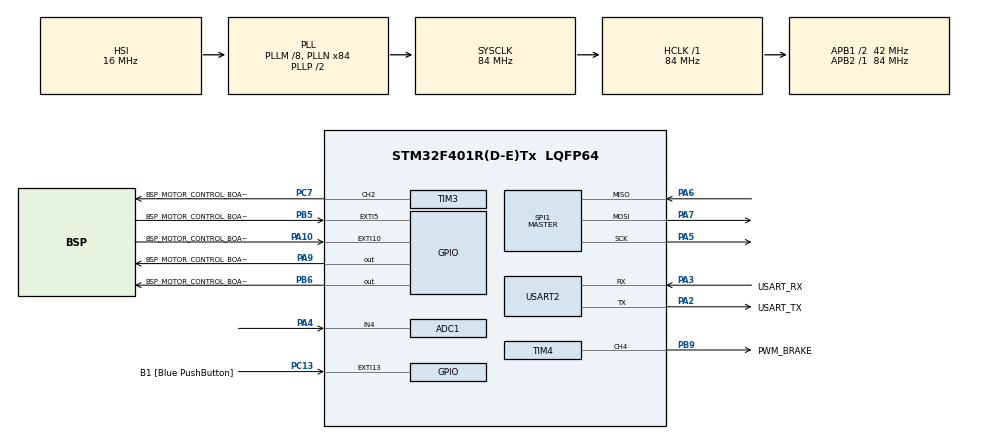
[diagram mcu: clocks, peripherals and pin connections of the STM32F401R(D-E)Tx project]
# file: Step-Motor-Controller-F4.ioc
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ADC1.Channel-4\#ChannelRegularConversion=ADC_CHANNEL_4
ADC1.NbrOfConversionFlag=1
ADC1.Rank-4\#ChannelRegularConversion=1
ADC1.SamplingTime-4\#ChannelRegularConversion=ADC_SAMPLETIME_3CYCLES
ADC1.master=1
Mcu.Family=STM32F4
Mcu.Name=STM32F401R(D-E)Tx
Mcu.Package=LQFP64
NVIC.EXTI15_10_IRQn=true\:0\:0\:false\:false\:true\:false\:true\:true
NVIC.EXTI9_5_IRQn=true\:0\:0\:false\:false\:true\:false\:true\:true
NVIC.PriorityGroup=NVIC_PRIORITYGROUP_4
NVIC.TIM2_IRQn=true\:15\:0\:true\:false\:true\:false\:false\:true
NVIC.TimeBase=TIM2_IRQn
NVIC.TimeBaseIP=TIM2
NVIC.USART2_IRQn=true\:0\:0\:true\:false\:true\:false\:true\:true
PA10.GPIO_Label=BSP_MOTOR_CONTROL_BOARD_FLAG
PA10.GPIO_ModeDefaultEXTI=GPIO_MODE_IT_FALLING
PA10.GPIO_PuPd=GPIO_PULLUP
PA10.Signal=GPXTI10
PA13.GPIO_Label=TMS
PA13.Mode=Serial_Wire
PA13.Signal=SYS_JTMS-SWDIO
PA14.GPIO_Label=TCK
PA14.Mode=Serial_Wire
PA14.Signal=SYS_JTCK-SWCLK
PA2.GPIO_Label=USART_TX
PA2.GPIO_Mode=GPIO_MODE_AF_PP
PA2.GPIO_PuPd=GPIO_NOPULL
PA2.GPIO_Speed=GPIO_SPEED_FREQ_LOW
PA2.Mode=Asynchronous
PA2.Signal=USART2_TX
PA3.GPIO_Label=USART_RX
PA3.GPIO_Mode=GPIO_MODE_AF_PP
PA3.GPIO_PuPd=GPIO_NOPULL
PA3.GPIO_Speed=GPIO_SPEED_FREQ_LOW
PA3.Mode=Asynchronous
PA3.Signal=USART2_RX
PA4.Signal=ADCx_IN4
PA5.GPIO_Speed=GPIO_SPEED_FREQ_LOW
PA5.Mode=Full_Duplex_Master
PA5.Signal=SPI1_SCK
PA6.GPIO_Speed=GPIO_SPEED_FREQ_LOW
PA6.Mode=Full_Duplex_Master
PA6.Signal=SPI1_MISO
PA7.GPIO_Speed=GPIO_SPEED_FREQ_LOW
PA7.Mode=Full_Duplex_Master
PA7.Signal=SPI1_MOSI
PA9.GPIO_Label=BSP_MOTOR_CONTROL_BOARD_STBY_RESET
PA9.Signal=GPIO_Output
PB5.GPIO_Label=BSP_MOTOR_CONTROL_BOARD_BUSY
PB5.GPIO_ModeDefaultEXTI=GPIO_MODE_IT_RISING_FALLING
PB5.GPIO_PuPd=GPIO_PULLUP
PB5.Signal=GPXTI5
PB6.GPIO_Label=BSP_MOTOR_CONTROL_BOARD_CS
PB6.GPIO_PuPd=GPIO_PULLUP
PB6.PinState=GPIO_PIN_SET
PB6.Signal=GPIO_Output
PB9.GPIO_Label=PWM_BRAKE
PB9.Signal=S_TIM4_CH4
PC13-ANTI_TAMP.GPIO_Label=B1 [Blue PushButton]
PC13-ANTI_TAMP.GPIO_ModeDefaultEXTI=GPIO_MODE_IT_FALLING
PC13-ANTI_TAMP.GPIO_PuPd=GPIO_NOPULL
PC13-ANTI_TAMP.Signal=GPXTI13
PC14-OSC32_IN.Mode=LSE-External-Oscillator
PC14-OSC32_IN.Signal=RCC_OSC32_IN
PC15-OSC32_OUT.Mode=LSE-External-Oscillator
PC15-OSC32_OUT.Signal=RCC_OSC32_OUT
PC7.GPIO_Label=BSP_MOTOR_CONTROL_BOARD_TIMER_STEP_CLOCK
PC7.Signal=S_TIM3_CH2
PH0\ -\ OSC_IN.Mode=HSE-External-Clock-Source
PH0\ -\ OSC_IN.Signal=RCC_OSC_IN
PH1\ -\ OSC_OUT.Mode=HSE-External-Clock-Source
PH1\ -\ OSC_OUT.Signal=RCC_OSC_OUT
ProjectManager.HeapSize=0x200
ProjectManager.StackSize=0x400
ProjectManager.TargetToolchain=STM32CubeIDE
RCC.48MHZClocksFreq_Value=24000000
RCC.AHBFreq_Value=84000000
RCC.APB1CLKDivider=RCC_HCLK_DIV2
RCC.APB1Freq_Value=42000000
RCC.APB1TimFreq_Value=84000000
RCC.APB2Freq_Value=84000000
RCC.APB2TimFreq_Value=84000000
RCC.CortexFreq_Value=84000000
RCC.HCLKFreq_Value=84000000
RCC.HSE_VALUE=8000000
RCC.HSI_VALUE=16000000
RCC.PLLM=8
RCC.PLLN=84
RCC.PLLQ=7
RCC.SYSCLKFreq_VALUE=84000000
RCC.SYSCLKSource=RCC_SYSCLKSOURCE_PLLCLK
RCC.VCOOutputFreq_Value=168000000
SH.ADCx_IN4.0=ADC1_IN4,IN4
SH.S_TIM3_CH2.0=TIM3_CH2,PWM Generation2 CH2
SH.S_TIM4_CH4.0=TIM4_CH4,PWM Generation4 CH4
SPI1.BaudRatePrescaler=SPI_BAUDRATEPRESCALER_32
SPI1.CLKPhase=SPI_PHASE_2EDGE
SPI1.CLKPolarity=SPI_POLARITY_HIGH
SPI1.Direction=SPI_DIRECTION_2LINES
SPI1.Mode=SPI_MODE_MASTER
SPI1.VirtualType=VM_MASTER
STMicroelectronics.X-CUBE-AZRTOS-F4.1.0.0.ThreadXCcRTOSJjThreadXJjCore=true
STMicroelectronics.X-CUBE-AZRTOS-F4.1.0.0.ThreadXCcRTOSJjThreadXJjLowOoPowerOosupport=true
STMicroelectronics.X-CUBE-AZRTOS-F4.1.0.0.ThreadXCcRTOSJjThreadXJjPerformanceInfo=true
STMicroelectronics.X-CUBE-AZRTOS-F4.1.0.0.ThreadXCcRTOSJjThreadXJjTraceXOosupport=true
STMicroelectronics.X-CUBE-AZRTOS-F4.1.0.0_IsAnAzureRtosMw=true
TIM3.Channel-PWM\ Generation2\ CH2=TIM_CHANNEL_2
TIM3.OC2Preload_PWM=DISABLE
TIM3.Period=0
TIM3.Prescaler=64-1
TIM4.Channel-PWM\ Generation4\ CH4=TIM_CHANNEL_4
TIM4.ClockDivision=TIM_CLOCKDIVISION_DIV2
TIM4.Period=0
TIM4.Prescaler=64
USART2.OverSampling=UART_OVERSAMPLING_8
USART2.VirtualMode=VM_ASYNC
VP_STMicroelectronics.X-CUBE-AZRTOS-F4_VS_RTOSJjThreadX_6.1.7_1.0.0.Mode=RTOSJjThreadX
VP_SYS_VS_tim2.Mode=TIM2
VP_TIM3_VS_ClockSourceINT.Mode=Internal
board=NUCLEO-F401RE

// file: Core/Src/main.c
/* USER CODE BEGIN Header */
/**
  ******************************************************************************
  * @file           : main.c
  * @brief          : Main program body
  ******************************************************************************
  * @attention
  *
  * Copyright (c) 2022 STMicroelectronics.
  * All rights reserved.
  *
  * This software is licensed under terms that can be found in the LICENSE file
  * in the root directory of this software component.
  * If no LICENSE file comes with this software, it is provided AS-IS.
  *
  ******************************************************************************
  */
/* USER CODE END Header */
#include "main.h"
#include "app_threadx.h"
#include "adc.h"
#include "spi.h"
#include "tim.h"
#include "usart.h"
#include "gpio.h"

/* USER CODE BEGIN Includes */
#include <stdio.h>
/* USER CODE END Includes */

void SystemClock_Config(void);

int main(void)
{

  /* MCU Configuration--------------------------------------------------------*/

  /* Reset of all peripherals, Initializes the Flash interface and the Systick. */
  HAL_Init();

  /* Configure the system clock */
  SystemClock_Config();

  /* Initialize all configured peripherals */
  MX_GPIO_Init();
  MX_USART2_UART_Init();
  MX_SPI1_Init();
  MX_TIM4_Init();
  MX_TIM3_Init();
  MX_ADC1_Init();
  /* USER CODE BEGIN 2 */
//  Powerstep01_Board_ReleaseReset(0);
//  HAL_GPIO_WritePin(BSP_MOTOR_CONTROL_BOARD_CS_GPIO_Port, BSP_MOTOR_CONTROL_BOARD_CS_Pin, GPIO_PIN_SET);
  /* USER CODE END 2 */

  MX_ThreadX_Init();
  /* Infinite loop */
  while (1)
  {

  }
}

void SystemClock_Config(void)
{
  RCC_OscInitTypeDef RCC_OscInitStruct = {0};
  RCC_ClkInitTypeDef RCC_ClkInitStruct = {0};

  /** Configure the main internal regulator output voltage
  */
  __HAL_RCC_PWR_CLK_ENABLE();
  __HAL_PWR_VOLTAGESCALING_CONFIG(PWR_REGULATOR_VOLTAGE_SCALE2);
  /** Initializes the RCC Oscillators according to the specified parameters
  * in the RCC_OscInitTypeDef structure.
  */
  RCC_OscInitStruct.OscillatorType = RCC_OSCILLATORTYPE_HSI;
  RCC_OscInitStruct.HSIState = RCC_HSI_ON;
  RCC_OscInitStruct.HSICalibrationValue = RCC_HSICALIBRATION_DEFAULT;
  RCC_OscInitStruct.PLL.PLLState = RCC_PLL_ON;
  RCC_OscInitStruct.PLL.PLLSource = RCC_PLLSOURCE_HSI;
  RCC_OscInitStruct.PLL.PLLM = 8;
  RCC_OscInitStruct.PLL.PLLN = 84;
  RCC_OscInitStruct.PLL.PLLP = RCC_PLLP_DIV2;
  RCC_OscInitStruct.PLL.PLLQ = 7;
  if (HAL_RCC_OscConfig(&RCC_OscInitStruct) != HAL_OK)
  {
    Error_Handler();
  }
  /** Initializes the CPU, AHB and APB buses clocks
  */
  RCC_ClkInitStruct.ClockType = RCC_CLOCKTYPE_HCLK|RCC_CLOCKTYPE_SYSCLK
                              |RCC_CLOCKTYPE_PCLK1|RCC_CLOCKTYPE_PCLK2;
  RCC_ClkInitStruct.SYSCLKSource = RCC_SYSCLKSOURCE_PLLCLK;
  RCC_ClkInitStruct.AHBCLKDivider = RCC_SYSCLK_DIV1;
  RCC_ClkInitStruct.APB1CLKDivider = RCC_HCLK_DIV2;
  RCC_ClkInitStruct.APB2CLKDivider = RCC_HCLK_DIV1;

  if (HAL_RCC_ClockConfig(&RCC_ClkInitStruct, FLASH_LATENCY_2) != HAL_OK)
  {
    Error_Handler();
  }
}

void HAL_TIM_PeriodElapsedCallback(TIM_HandleTypeDef *htim)
{
  if (htim->Instance == TIM2) {
    HAL_IncTick();
  }
}

void Error_Handler(void)
{
  __disable_irq();
  while (1)
  {
  }
}
